# GD32L235x register map
File version: 1.0
CPU: CM23 r1p0, little endian, no MPU, no FPU, 2 interrupt priority bits
Registers are 32-bit, read-write, reset 0x0 unless marked. A register's access mark holds for its fields unless they carry their own. Offsets are from the block's base; [hi:lo] are bit positions; {n}, {i} and the like mark numbered series.

## PMU — Power management unit
Base 0x40007000
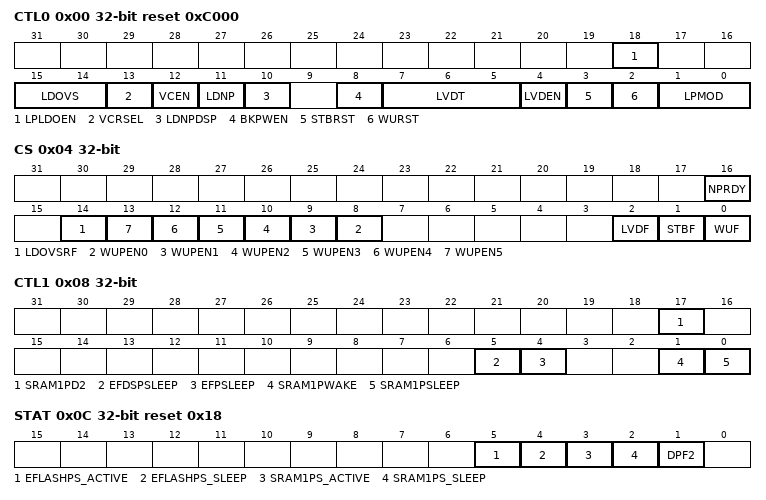
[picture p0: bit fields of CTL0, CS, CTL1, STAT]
0x00 CTL0 reset 0xC000 — power control register 0
  [18] LPLDOEN — Low power LDO
  [15:14] LDOVS — LDO output voltage select
  [13] VCRSEL — VBAT battery charging resistor selection
  [12] VCEN — VBAT battery charging enable
  [11] LDNP — Low-driver mode when use normal power LDO in Run/Sleep mode
  [10] LDNPDSP — Low-driver mode when use normal power LDO in Deep-sleep mode
  [8] BKPWEN — Backup Domain Write Enable
  [7:5] LVDT — Low Voltage Detector Threshold
  [4] LVDEN — Low Voltage Detector Enable
  [3] STBRST — Standby Flag Reset
  [2] WURST — Wakeup Flag Reset
  [1:0] LPMOD — Select the lowpower mode to enter
0x04 CS access per field — power control/status register
  [16] NPRDY rw — Normal power LDO ready flag
  [14] LDOVSRF rw — LDO voltage select ready flag
  [n+8] WUPEN{n} rw (n=0..5) — WKUP pin{n} Enable
  [2] LVDF ro — Low Voltage Detector Status Flag
  [1] STBF ro — Standby flag
  [0] WUF ro — Wakeup flag
0x08 CTL1 — power control register 1
  [17] SRAM1PD2 — Power state of 16KB SRAM when enter s Deep sleep2 mode
  [5] EFDSPSLEEP — EFLASH macro powercontrl when in Deep-sleep
  [4] EFPSLEEP — EFLASH macro powercontrol when in Run
  [1] SRAM1PWAKE — SRAM1 wakeup
  [0] SRAM1PSLEEP — SRAM1 go to power-off
0x0C STAT reset 0x18 — power Status register (PMU_
  [5] EFLASHPS_ACTIVE — EFLASH macro is in active state
  [4] EFLASHPS_SLEEP — EFLASH macro is in sleep state
  [3] SRAM1PS_ACTIVE — SRAM1 is in active state
  [2] SRAM1PS_SLEEP — SRAM1 is in sleep state
  [1] DPF2 — This bit is Deep-sleep2 mode status
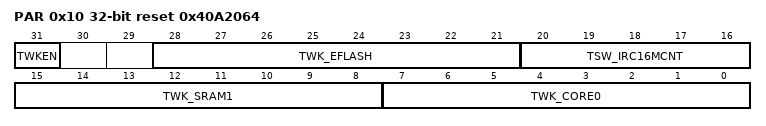
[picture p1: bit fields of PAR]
0x10 PAR reset 0x40A2064 — Parameter register
  [31] TWKEN — Use software value when wake up Deep-sleep2 or not
  [28:21] TWK_EFLASH — EFLASH wake up counter
  [20:16] TSW_IRC16MCNT — When enter deep-sleep mode, switch to IRC16M clock
  [15:8] TWK_SRAM1 — Wakeup time of power switch of SRAM1 domain
  [7:0] TWK_CORE0 — Wakeup time of power switch of COREOFF0 domain

## SLCD — Segment LCD controller
Base 0x40002400
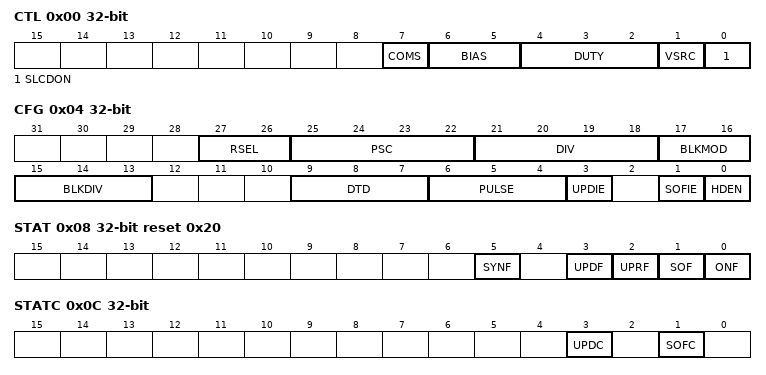
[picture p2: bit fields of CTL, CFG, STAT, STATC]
0x00 CTL — Control register
  [7] COMS — Common/segment padselect
  [6:5] BIAS — Bias select
  [4:2] DUTY — Duty select
  [1] VSRC — SLCD voltage source
  [0] SLCDON — SLCD controller start
0x04 CFG — SLCD configuration register
  [27:26] RSEL — Weak driving resistance select
  [25:22] PSC — SLCD clock prescaler
  [21:18] DIV — SLCD clock divider
  [17:16] BLKMOD — Blink mode
  [15:13] BLKDIV — Blink frequency divider
  [9:7] DTD — Dead time duration
  [6:4] PULSE — Pulse on duration
  [3] UPDIE — SLCD update done interrupt enable
  [1] SOFIE — Start of frame interrupt enable
  [0] HDEN — High drive enable
0x08 STAT access per field reset 0x20 — SLCD status flag register
  [5] SYNF ro — SLCD_CFG register synchronization flag
  [3] UPDF ro — Update SLCD data done flag
  [2] UPRF rw — Update SLCD data request flag
  [1] SOF ro — Start of frame flag
  [0] ONF ro — SLCD controller on flag
0x0C STATC — SLCD status flag clear register
  [3] UPDC — SLCD data update done clear bit
  [1] SOFC — Start of frame flag clear
{0x14+8i} DATA{i} (i=0..7) — SLCD display data register
  [31:0] SEG_DATA{i} — Each bit corresponds to one segment to display

## SPI0 — Serial peripheral interface
Base 0x40013000
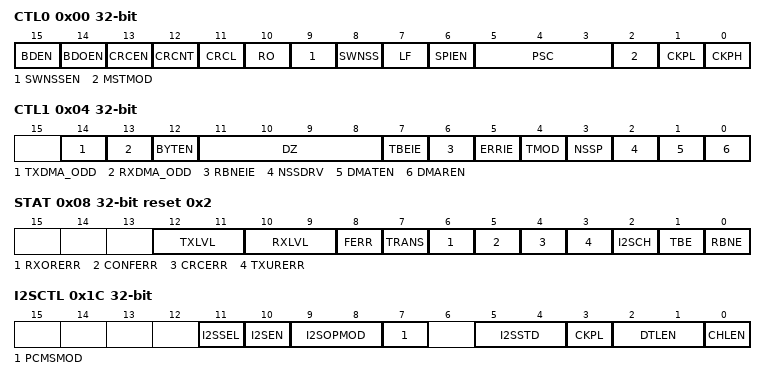
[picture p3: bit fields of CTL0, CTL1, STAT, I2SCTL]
0x00 CTL0 — control register 0
  [15] BDEN — Bidirectional enable
  [14] BDOEN — Bidirectional Transmit output enable
  [13] CRCEN — Hardware CRC calculation enable
  [12] CRCNT — CRC transfer next
  [11] CRCL — CRC length
  [10] RO — Receive only
  [9] SWNSSEN — NSS Software Mode Selection
  [8] SWNSS — NSS Pin Selection In NSS Software Mode
  [7] LF — LSB First Mode
  [6] SPIEN — SPI enable
  [5:3] PSC — Master Clock Prescaler Selection
  [2] MSTMOD — Master Mode Enable
  [1] CKPL — Clock Polarity Selection
  [0] CKPH — Clock Phase Selection
0x04 CTL1 — control register 1
  [14] TXDMA_ODD — Odd bytes in TX DMA channel
  [13] RXDMA_ODD — Odd bytes in RX DMA channel
  [12] BYTEN — Byte access enable
  [11:8] DZ — Date size
  [7] TBEIE — Transmit Buffer Empty Interrupt Enable
  [6] RBNEIE — Receive Buffer Not Empty Interrupt Enable
  [5] ERRIE — Error interrupt enable
  [4] TMOD — SPI TI Mode Enable
  [3] NSSP — SPI NSS Pulse Mode Enable
  [2] NSSDRV — NSS output enable
  [1] DMATEN — Tx buffer DMA enable
  [0] DMAREN — Rx buffer DMA enable
0x08 STAT access per field reset 0x2 — status register
  [12:11] TXLVL ro — Tx FIFO level
  [10:9] RXLVL ro — Rx FIFO level
  [8] FERR rw — Format Error
  [7] TRANS ro — Transmitting ongoing Bit
  [6] RXORERR ro — Reception Overrun Error Bit
  [5] CONFERR ro — SPI Configuration error
  [4] CRCERR rw — SPI CRC Error Bit
  [3] TXURERR ro — Transmission underrun error bit
  [2] I2SCH ro — I2S channel side
  [1] TBE ro — Transmit Buffer Empty
  [0] RBNE ro — Receive Buffer Not Empty
0x0C DATA
  [15:0] DATA
0x10 CPCPOLY reset 0x7 — CRC polynomial register
  [15:0] CRCPOLY
0x14 RCRC ro — RX CRC register
  [15:0] RCRC — RX RCR register
0x18 TCRC ro — TX CRC register
  [15:0] TCRC — Tx CRC register
0x1C I2SCTL — I2S configuration register
  [11] I2SSEL — I2S mode selection
  [10] I2SEN — I2S Enable
  [9:8] I2SOPMOD — I2S configuration mode
  [7] PCMSMOD — PCM frame synchronization
  [5:4] I2SSTD — I2S standard selection
  [3] CKPL — Idle state clock polarity
  [2:1] DTLEN — Data length to be transferred
  [0] CHLEN — Channel length (number of bits per audio channel)
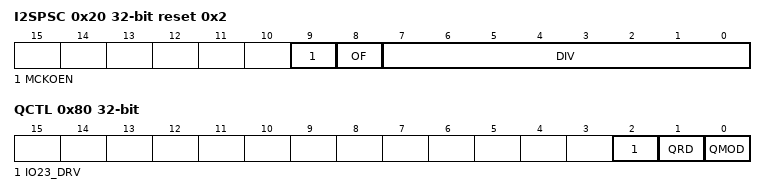
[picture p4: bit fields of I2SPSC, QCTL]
0x20 I2SPSC reset 0x2 — I2S prescaler register
  [9] MCKOEN — I2S_MCK output enable
  [8] OF — Odd factor for the prescaler
  [7:0] DIV — Dividing factor for the prescaler
0x80 QCTL — SPI quad wird control register
  [2] IO23_DRV — Drive IO2 and IO3 enable
  [1] QRD — Quad wire read select
  [0] QMOD — Quad wire mode enable
